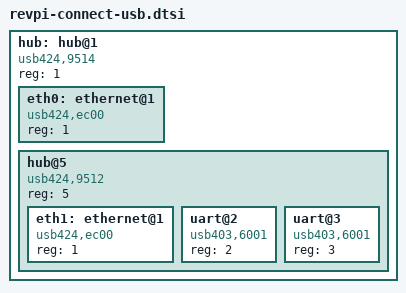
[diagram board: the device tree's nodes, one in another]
// SPDX-License-Identifier: GPL-2.0-only
// SPDX-FileCopyrightText: Copyright 2025 KUNBUS GmbH

/*
 * Common USB hierarchy include for RevPi Connect (+)/S/SE
 */
hub: hub@1 {
	/* SMSC LAN9514 */
	compatible = "usb424,9514";
	reg = <1>;
	#address-cells = <1>;
	#size-cells = <0>;

	eth0: ethernet@1 {
		compatible = "usb424,ec00";
		reg = <1>;
	};

	hub@5 {
		/* SMSC LAN9512 */
		compatible = "usb424,9512";
		reg = <5>;
		#address-cells = <1>;
		#size-cells = <0>;

		eth1: ethernet@1 {
			compatible = "usb424,ec00";
			reg = <1>;
		};

		uart@2 {
			/* FTDI FT232R (front) */
			compatible = "usb403,6001";
			reg = <2>;
		};

		uart@3 {
			/* FTDI FT232R (conbridge) */
			compatible = "usb403,6001";
			reg = <3>;
		};
	};
};
